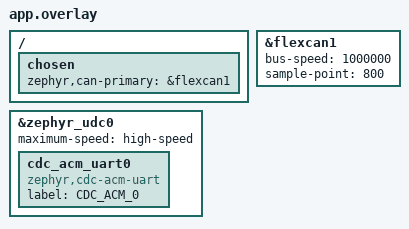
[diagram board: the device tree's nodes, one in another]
&flexcan1 {
    status = "okay";
    /* 1 Mbps (padrao dos nodes novos). Nodes ainda em 500 kbps: CANBR_LOCAL 500000 e
     * depois CANBR 1000000 migra todos de uma vez. */
    bus-speed = <1000000>;
    sample-point = <800>;
};

/ {
    chosen {
        zephyr,can-primary = &flexcan1;
    };
};

&zephyr_udc0 {
    status = "okay";
    maximum-speed = "high-speed";

    cdc_acm_uart0: cdc_acm_uart0 {
        compatible = "zephyr,cdc-acm-uart";
        label = "CDC_ACM_0";
        status = "okay";
    };
};
